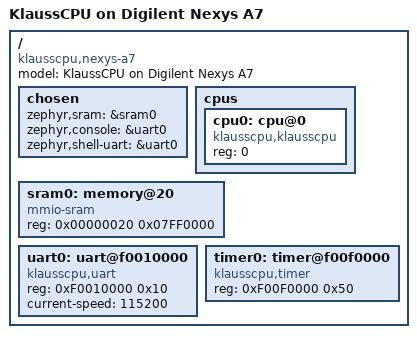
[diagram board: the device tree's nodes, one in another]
/dts-v1/;

/ {
	#address-cells = <1>;
	#size-cells = <1>;
	model = "KlaussCPU on Digilent Nexys A7";
	compatible = "klausscpu,nexys-a7";

	chosen {
		zephyr,sram = &sram0;
		zephyr,console = &uart0;
		zephyr,shell-uart = &uart0;
	};

	cpus {
		#address-cells = <1>;
		#size-cells = <0>;
		cpu0: cpu@0 {
			compatible = "klausscpu,klausscpu";
			device_type = "cpu";
			reg = <0>;
		};
	};

	/*
	 * 128 MiB RAM.  First 32 bytes (0x00-0x1F) are the hardware heap
	 * header; code starts at 0x20.  Top 64 KiB reserved for stack.
	 * Zephyr places its BSS/data here; kernel + app live in .text.
	 */
	sram0: memory@20 {
		compatible = "mmio-sram";
		reg = <0x00000020 0x07FF0000>;
	};

	/* KlaussCPU UART — single MMIO byte at 0xF0010000 (TX/RX register). */
	uart0: uart@f0010000 {
		compatible = "klausscpu,uart";
		reg = <0xF0010000 0x10>;
		status = "okay";
		current-speed = <115200>;
	};

	/* Interrupt controller + timer at 0xF00F_0000. */
	timer0: timer@f00f0000 {
		compatible = "klausscpu,timer";
		reg = <0xF00F0000 0x50>;
		status = "okay";
	};
};
